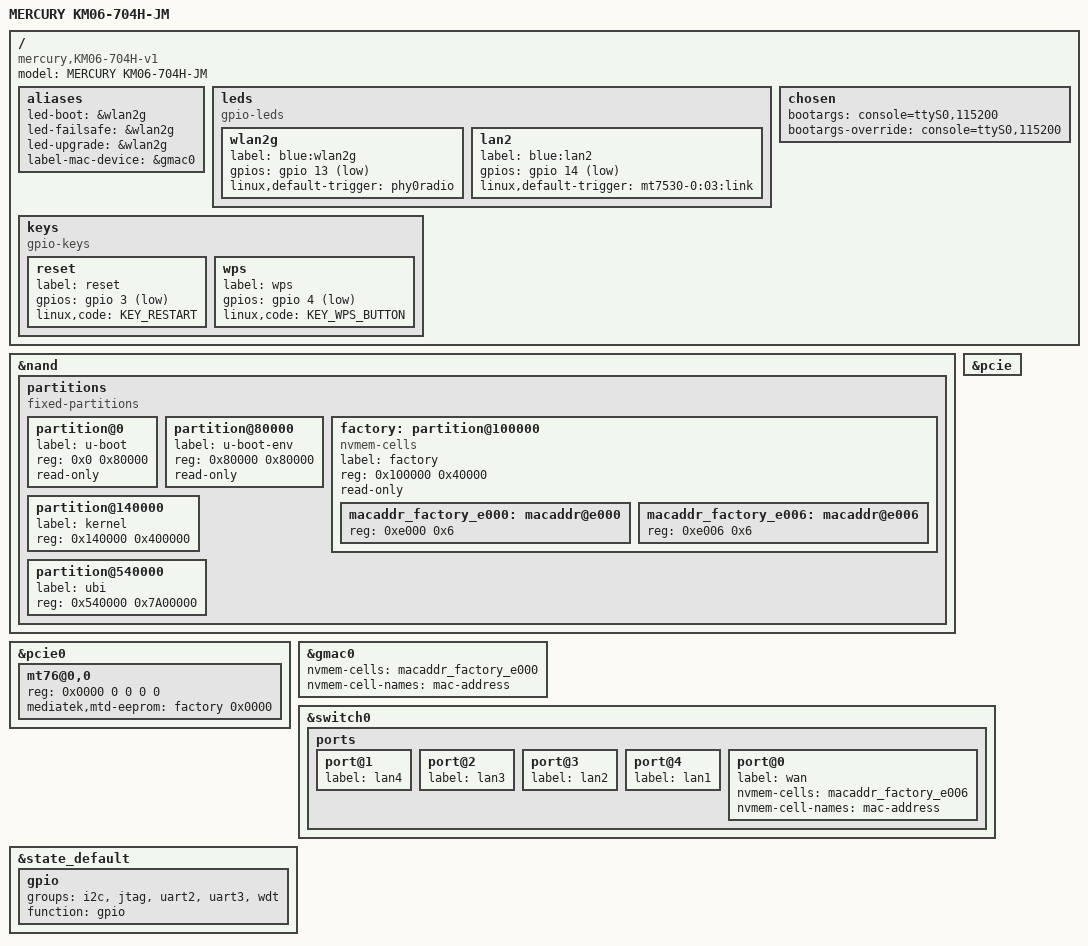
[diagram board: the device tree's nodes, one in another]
// SPDX-License-Identifier: GPL-2.0-or-later OR MIT

#include "mt7621.dtsi"

#include <dt-bindings/gpio/gpio.h>
#include <dt-bindings/input/input.h>

/ {
	compatible = "mercury,KM06-704H-v1", "mediatek,mt7621-soc";
	model = "MERCURY KM06-704H-JM";


	aliases {
		led-boot = &wlan2g;
		led-failsafe = &wlan2g;
		led-upgrade = &wlan2g;
		label-mac-device = &gmac0;
	};

	leds {
		compatible = "gpio-leds";

		wlan2g: wlan2g {
			label = "blue:wlan2g";
			gpios = <&gpio 13 GPIO_ACTIVE_LOW>;
			linux,default-trigger = "phy0radio";
		};

		lan2  {
                        label = "blue:lan2";
                        gpios = <&gpio 14 GPIO_ACTIVE_LOW>;
                        linux,default-trigger = "mt7530-0:03:link";
                };
	};

	chosen {
		bootargs = "console=ttyS0,115200";
		bootargs-override = "console=ttyS0,115200";
	};
	keys {
		compatible = "gpio-keys";

		reset {
			label = "reset";
			gpios = <&gpio 3 GPIO_ACTIVE_LOW>;
			linux,code = <KEY_RESTART>;
		};

		wps {
			label = "wps";
			gpios = <&gpio 4 GPIO_ACTIVE_LOW>;
			linux,code = <KEY_WPS_BUTTON>;
		};

	};
};

&nand {
	status = "okay";

	partitions {
		compatible = "fixed-partitions";
		#address-cells = <1>;
		#size-cells = <1>;

		partition@0 {
			label = "u-boot";
			reg = <0x0 0x80000>;
			read-only;
		};

		partition@80000 {
			label = "u-boot-env";
			reg = <0x80000 0x80000>;
			read-only;
		};

		factory: partition@100000 {
			label = "factory";
			reg = <0x100000 0x40000>;
			read-only;
		};

		partition@140000 {
			label = "kernel";
			reg = <0x140000 0x400000>;
		};

		partition@540000 {
			label = "ubi";
			reg = <0x540000 0x7A00000>;
		};
	};
};

&pcie {
	status = "okay";
};

&pcie0 {
	mt76@0,0 {
		reg = <0x0000 0 0 0 0>;
		mediatek,mtd-eeprom = <&factory 0x0000>;
		/*led {
			led-sources = <3>;
			led-active-low;
		};*/
	};
};


&gmac0 {
	nvmem-cells = <&macaddr_factory_e000>;
	nvmem-cell-names = "mac-address";
};

&switch0 {
	ports {
		port@1 {
			status = "okay";
			label = "lan4";
		};

		port@2 {
			status = "okay";
			label = "lan3";
		};

		port@3 {
			status = "okay";
			label = "lan2";
		};

		port@4 {
			status = "okay";
			label = "lan1";
		};

		port@0 {
			status = "okay";
			label = "wan";
			nvmem-cells = <&macaddr_factory_e006>;
			nvmem-cell-names = "mac-address";
		};
	};
};

&state_default {
	gpio {
		groups = "i2c", "jtag", "uart2", "uart3", "wdt";
		function = "gpio";
	};
};

&factory {
	compatible = "nvmem-cells";
	#address-cells = <1>;
	#size-cells = <1>;

	macaddr_factory_e000: macaddr@e000 {
		reg = <0xe000 0x6>;
	};

	macaddr_factory_e006: macaddr@e006 {
		reg = <0xe006 0x6>;
	};
};
